# STM32F101_iown register map
Vendor: iown-homecontrol; Series: CM3; File version: 1.3
CPU: CM3 r1p1, little endian, no MPU, no FPU, VTOR, 4 interrupt priority bits
Registers are 32-bit, read-write, reset 0x0 unless marked. A register's access mark holds for its fields unless they carry their own. Offsets are from the block's base; [hi:lo] are bit positions; {n}, {i} and the like mark numbered series; 'fields as' and 'values as' point back to an identical list.

## TIM1 — Advanced timer
Base 0x40012C00
Same registers: TIM8 0x40013400
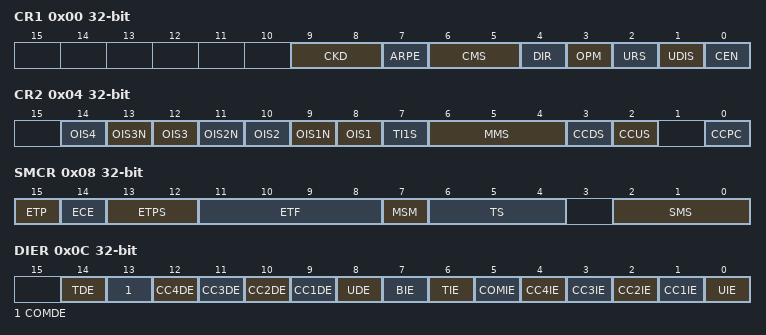
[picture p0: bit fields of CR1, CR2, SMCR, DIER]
0x00 CR1 — control register 1
  [9:8] CKD — Clock division
    0=Div1 (t_DTS = t_CK_INT); 1=Div2 (t_DTS = 2 x t_CK_INT); 2=Div4 (t_DTS = 4 x t_CK_INT)
  [7] ARPE — Auto-reload preload enable
    0=Disabled (TIMx_APRR register is not buffered); 1=Enabled (TIMx_APRR register is buffered)
  [6:5] CMS — Center-aligned mode selection
    0=EdgeAligned (The counter counts up or down depending on the direction bit); 1=CenterAligned1 (The counter counts up and down alternatively. Output compare interrupt flags are set only when the counter is counting down.); 2=CenterAligned2 (The counter counts up and down alternatively. Output compare interrupt flags are set only when the counter is counting up.); 3=CenterAligned3 (The counter counts up and down alternatively. Output compare interrupt flags are set both when the counter is counting up or down.)
  [4] DIR — Direction
    0=Up (Counter used as upcounter); 1=Down (Counter used as downcounter)
  [3] OPM — One-pulse mode
    0=Disabled (Counter is not stopped at update event); 1=Enabled (Counter stops counting at the next update event (clearing the CEN bit))
  [2] URS — Update request source
    0=AnyEvent (Any of counter overflow/underflow, setting UG, or update through slave mode, generates an update interrupt or DMA request); 1=CounterOnly (Only counter overflow/underflow generates an update interrupt or DMA request)
  [1] UDIS — Update disable
    0=Enabled (Update event enabled); 1=Disabled (Update event disabled)
  [0] CEN — Counter enable
    0=Disabled (Counter disabled); 1=Enabled (Counter enabled)
0x04 CR2 — control register 2
  [2n+6] OIS{n} (n=1..4) — Output Idle state {n}
  [13] OIS3N — Output Idle state 3
  [11] OIS2N — Output Idle state 2
  [9] OIS1N — Output Idle state 1
  [7] TI1S — TI1 selection
    0=Normal (The TIMx_CH1 pin is connected to TI1 input); 1=XOR (The TIMx_CH1, CH2, CH3 pins are connected to TI1 input)
  [6:4] MMS — Master mode selection
    0=Reset (The UG bit from the TIMx_EGR register is used as trigger output); 1=Enable (The counter enable signal, CNT_EN, is used as trigger output); 2=Update (The update event is selected as trigger output); 3=ComparePulse (The trigger output send a positive pulse when the CC1IF flag it to be set, as soon as a capture or a compare match occurred); {v}=CompareOC{v-3} (OC{v-3}REF signal is used as trigger output) (v=4..7)
  [3] CCDS — Capture/compare DMA selection
    0=OnCompare (CCx DMA request sent when CCx event occurs); 1=OnUpdate (CCx DMA request sent when update event occurs)
  [2] CCUS — Capture/compare control update selection
  [0] CCPC — Capture/compare preloaded control
0x08 SMCR — slave mode control register
  [15] ETP — External trigger polarity
    0=NotInverted (ETR is noninverted, active at high level or rising edge); 1=Inverted (ETR is inverted, active at low level or falling edge)
  [14] ECE — External clock enable
    0=Disabled (External clock mode 2 disabled); 1=Enabled (External clock mode 2 enabled. The counter is clocked by any active edge on the ETRF signal.)
  [13:12] ETPS — External trigger prescaler
    0=Div1 (Prescaler OFF); 1=Div2 (ETRP frequency divided by 2); 2=Div4 (ETRP frequency divided by 4); 3=Div8 (ETRP frequency divided by 8)
  [11:8] ETF — External trigger filter
    0=No filter, sampling is done at fDTS; 1=FCK_INT_N2 (fSAMPLING=fCK_INT, N=2); 2=FCK_INT_N4 (fSAMPLING=fCK_INT, N=4); 3=FCK_INT_N8 (fSAMPLING=fCK_INT, N=8); 4=FDTS_Div2_N6 (fSAMPLING=fDTS/2, N=6); 5=FDTS_Div2_N8 (fSAMPLING=fDTS/2, N=8); 6=FDTS_Div4_N6 (fSAMPLING=fDTS/4, N=6); 7=FDTS_Div4_N8 (fSAMPLING=fDTS/4, N=8); 8=FDTS_Div8_N6 (fSAMPLING=fDTS/8, N=6); 9=FDTS_Div8_N8 (fSAMPLING=fDTS/8, N=8); 10=FDTS_Div16_N5 (fSAMPLING=fDTS/16, N=5); 11=FDTS_Div16_N6 (fSAMPLING=fDTS/16, N=6); 12=FDTS_Div16_N8 (fSAMPLING=fDTS/16, N=8); 13=FDTS_Div32_N5 (fSAMPLING=fDTS/32, N=5); 14=FDTS_Div32_N6 (fSAMPLING=fDTS/32, N=6); 15=FDTS_Div32_N8 (fSAMPLING=fDTS/32, N=8)
  [7] MSM — Master/Slave mode
    0=NoSync (No action); 1=Sync (The effect of an event on the trigger input (TRGI) is delayed to allow a perfect synchronization between the current timer and its slaves (through TRGO). It is useful if we want to synchronize several timers on a single external event.)
  [6:4] TS — Trigger selection
    0=ITR0 (Internal Trigger 0 (ITR0)); 1=ITR1 (Internal Trigger 1 (ITR1)); 2=ITR2 (Internal Trigger 2 (ITR2)); 4=TI1F_ED (TI1 Edge Detector (TI1F_ED)); 5=TI1FP1 (Filtered Timer Input 1 (TI1FP1)); 6=TI2FP2 (Filtered Timer Input 2 (TI2FP2)); 7=ETRF (External Trigger input (ETRF))
  [2:0] SMS — Slave mode selection
    0=Disabled (Slave mode disabled - if CEN = 1 then the prescaler is clocked directly by the internal clock.); 1=Encoder mode 1 - Counter counts up/down on TI2FP1 edge depending on TI1FP2 level; 2=Encoder mode 2 - Counter counts up/down on TI1FP2 edge depending on TI2FP1 level; 3=Encoder mode 3 - Counter counts up/down on both TI1FP1 and TI2FP2 edges depending on the level of the other input; 4=Reset Mode - Rising edge of the selected trigger input (TRGI) reinitializes the counter and generates an update of the registers; 5=Gated Mode - The counter clock is enabled when the trigger input (TRGI) is high. The counter stops (but is not reset) as soon as the trigger becomes low. Both start and stop of the counter are controlled.; 6=Trigger Mode - The counter starts at a rising edge of the trigger TRGI (but it is not reset). Only the start of the counter is controlled.; 7=Ext_Clock_Mode (External Clock Mode 1 - Rising edges of the selected trigger (TRGI) clock the counter.)
0x0C DIER — DMA/Interrupt enable register
  [14] TDE — Trigger DMA request enable
    0=Disabled (Trigger DMA request disabled); 1=Enabled (Trigger DMA request enabled)
  [13] COMDE — COM DMA request enable
  [12] CC4DE — Capture/Compare 4 DMA request enable
  [11] CC3DE — Capture/Compare 3 DMA request enable
  [10] CC2DE — Capture/Compare 2 DMA request enable
  [9] CC1DE — Capture/Compare 1 DMA request enable
    0=Disabled (CCx DMA request disabled); 1=Enabled (CCx DMA request enabled)
  [8] UDE — Update DMA request enable
    0=Disabled (Update DMA request disabled); 1=Enabled (Update DMA request enabled)
  [7] BIE — Break interrupt enable
  [6] TIE — Trigger interrupt enable
    0=Disabled (Trigger interrupt disabled); 1=Enabled (Trigger interrupt enabled)
  [5] COMIE — COM interrupt enable
  [4] CC4IE — Capture/Compare 4 interrupt enable
  [3] CC3IE — Capture/Compare 3 interrupt enable
  [2] CC2IE — Capture/Compare 2 interrupt enable
  [1] CC1IE — Capture/Compare 1 interrupt enable
    0=Disabled (CCx interrupt disabled); 1=Enabled (CCx interrupt enabled)
  [0] UIE — Update interrupt enable
    0=Disabled (Update interrupt disabled); 1=Enabled (Update interrupt enabled)
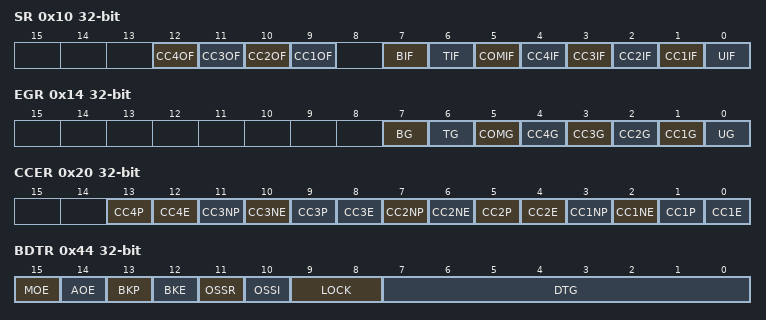
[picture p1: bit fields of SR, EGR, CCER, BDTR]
0x10 SR — status register
  [12] CC4OF write-0-clears — Capture/Compare 4 overcapture flag
    on read: 1=Overcapture (The counter value has been captured in TIMx_CCRx register while CCxIF flag was already set) | on write: 0=Clear flag
  [11] CC3OF write-0-clears — Capture/Compare 3 overcapture flag
    values as CC4OF
  [10] CC2OF write-0-clears — Capture/compare 2 overcapture flag
    values as CC4OF
  [9] CC1OF write-0-clears — Capture/Compare 1 overcapture flag
    values as CC4OF
  [7] BIF — Break interrupt flag
  [6] TIF write-0-clears — Trigger interrupt flag
    on read: 0=No trigger event occurred; 1=Trigger interrupt pending | on write: 0=Clear flag
  [5] COMIF — COM interrupt flag
  [4] CC4IF write-0-clears — Capture/Compare 4 interrupt flag
    on read: 1=Match (If CC1 is an output: The content of the counter TIMx_CNT matches the content of the TIMx_CCR1 register. If CC1 is an input: The counter value has been captured in TIMx_CCR1 register.) | on write: 0=Clear flag
  [3] CC3IF write-0-clears — Capture/Compare 3 interrupt flag
    values as CC4IF
  [2] CC2IF write-0-clears — Capture/Compare 2 interrupt flag
    values as CC4IF
  [1] CC1IF write-0-clears — Capture/compare 1 interrupt flag
    values as CC4IF
  [0] UIF — Update interrupt flag
    0=Clear (No update occurred); 1=UpdatePending (Update interrupt pending.)
0x14 EGR wo — event generation register
  [7] BG — Break generation
  [6] TG — Trigger generation
    on write: 1=Trigger (The TIF flag is set in TIMx_SR register. Related interrupt or DMA transfer can occur if enabled.)
  [5] COMG — Capture/Compare control update generation
  [4] CC4G — Capture/compare 4 generation
  [3] CC3G — Capture/compare 3 generation
  [2] CC2G — Capture/compare 2 generation
  [1] CC1G — Capture/compare 1 generation
    on write: 1=Trigger (If CC1 is an output: CC1IF flag is set, Corresponding interrupt or DMA request is sent if enabled. If CC1 is an input: The current value of the counter is captured in TIMx_CCR1 register.)
  [0] UG — Update generation
    on write: 1=Update (Re-initializes the timer counter and generates an update of the registers.)
0x18 CCMR1 — capture/compare mode register 1
0x1C CCMR2 — capture/compare mode register 2
0x20 CCER — capture/compare enable register
  [13] CC4P — Capture/Compare 3 output Polarity
  [4n-4] CC{n}E (n=1..4) — Capture/Compare {n} output enable
  [11] CC3NP — Capture/Compare 3 output Polarity
  [10] CC3NE — Capture/Compare 3 complementary output enable
  [9] CC3P — Capture/Compare 3 output Polarity
  [7] CC2NP — Capture/Compare 2 output Polarity
  [6] CC2NE — Capture/Compare 2 complementary output enable
  [5] CC2P — Capture/Compare 2 output Polarity
  [3] CC1NP — Capture/Compare 1 output Polarity
  [2] CC1NE — Capture/Compare 1 complementary output enable
  [1] CC1P — Capture/Compare 1 output Polarity
0x24 CNT — counter
  [15:0] CNT — counter value
0x28 PSC — prescaler
  [15:0] PSC — Prescaler value
0x2C ARR — auto-reload register
  [15:0] ARR — Auto-reload value
0x30 RCR — repetition counter register
  [7:0] REP — Repetition counter value
{0x30+4i} CCR{i} (i=1..4) — capture/compare register
  [15:0] CCR — Capture/Compare value
0x44 BDTR — break and dead-time register
  [15] MOE — Main output enable
    0=DisabledIdle (OC/OCN are disabled or forced idle depending on OSSI); 1=Enabled (OC/OCN are enabled if CCxE/CCxNE are set)
  [14] AOE — Automatic output enable
  [13] BKP — Break polarity
  [12] BKE — Break enable
  [11] OSSR — Off-state selection for Run mode
    0=Disabled (When inactive, OC/OCN outputs are disabled); 1=IdleLevel (When inactive, OC/OCN outputs are enabled with their inactive level)
  [10] OSSI — Off-state selection for Idle mode
    0=Disabled (When inactive, OC/OCN outputs are disabled); 1=IdleLevel (When inactive, OC/OCN outputs are forced to idle level)
  [9:8] LOCK — Lock configuration
  [7:0] DTG — Dead-time generator setup
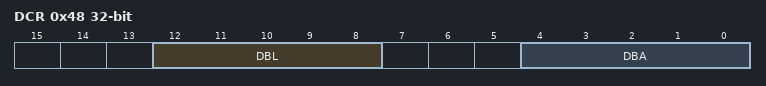
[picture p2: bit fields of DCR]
0x48 DCR — DMA control register
  [12:8] DBL range 0..18 — DMA burst length
  [4:0] DBA — DMA base address
0x4C DMAR — DMA address for full transfer
  [15:0] DMAB — DMA register for burst accesses
